# TMS320F28M35x_M3 register map
Vendor: Texas Instruments; Series: C2000 Concerto F28M35x; File version: 0.2.0-generated
CPU: CM3 r2p1, little endian, no MPU, no FPU, 3 interrupt priority bits
Registers are 32-bit, read-write, reset 0x0 unless marked. A register's access mark holds for its fields unless they carry their own. Offsets are from the block's base; [hi:lo] are bit positions; {n}, {i} and the like mark numbered series.

## DEVEMU — DEV EMU REGS Registers
Base 0x00000880
0x00 DEVICECNF — Device Configuration Register
0x02 PARTID 16-bit — Device ID Register
0x03 REVID 16-bit — Revision Register
{0x6+2i} CCNF{i} (i=0..4) — C28 Peripheral Configuration {i}
0x46 MEMCNF — M3 Memory Configuartion Register

## CSM — DCSM REGS Registers
Base 0x00000AE0
{0x0+2i} Z1_CSMKEY{i} (i=0..3) — CSMKEY{i} Register for C28X-Zone-1 security Zone
0x0F Z1_CR 16-bit — Status and Control Register for C28X-Zone-1 security Zone
0x10 Z1_ECSLKEY0 — ECSLKEY0 Register for C28X-Zone-1 security Zone
0x12 Z1_ECSLKEY1 — ECSLKEY1 Register for C28X-Zone-1 security Zone
0x15 Z1_EXEONLYR 16-bit — Execute-Only Select Register for flash sectors

## CPUTIMER — CPU Timer Registers
Base 0x00000C00
{0x0+8i} TIMER{i}TIM 16-bit (i=0..2) — CPU-Timer {i}, Counter Register
{0x1+8i} TIMER{i}TIMH 16-bit (i=0..2) — CPU-Timer {i}, Counter Register High
{0x2+8i} TIMER{i}PRD 16-bit (i=0..2) — CPU-Timer {i}, Period Register
{0x3+8i} TIMER{i}PRDH 16-bit (i=0..2) — CPU-Timer {i}, Period Register High
{0x4+8i} TIMER{i}TCR 16-bit (i=0..2) — CPU-Timer {i}, Control Register
{0x6+8i} TIMER{i}TPR 16-bit (i=0..2) — CPU-Timer {i}, Prescale Register
{0x7+8i} TIMER{i}TPRH 16-bit (i=0..2) — CPU-Timer {i}, Prescale Register High

## PIECTRL — Peripheral Interrupt Expansion Registers
Base 0x00000CE0
0x00 PIECTRL 16-bit — PIE, Control Register
0x01 PIEACK 16-bit — PIE, Acknowledge Register
{0x0+2i} PIEIER{i} 16-bit (i=1..12) — PIE, INT{i} Group Enable Register
{0x1+2i} PIEIFR{i} 16-bit (i=1..12) — PIE, INT{i} Group Flag Register

## FPU — Floating-Point Unit Single Precision Registers
Base 0x00000F00
0x00 RB — Repeat Block Register
  [31] RAS — Repeat block shadow active
  [30] RA — Repeat block active
  [31:29] RSIZE — Repeat block size
  [28:22] RE — Repeat block end
  [30:15] RC — Repeat count
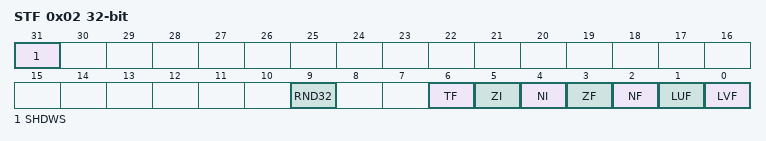
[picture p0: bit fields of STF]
0x02 STF — Floating-Point Status Register
  [31] SHDWS — Shadow mode status
  [9] RND32 — Rounding mode
  [6] TF — Test flag
  [5] ZI — Zero integer flag
  [4] NI — Negative integer flag
  [3] ZF — Zero float flag
  [2] NF — Negative flaot flag
  [1] LUF — Latched underflow
  [0] LVF — Latched overflow
{0x12+4i} R{i}H (i=0..7)

## DMA — DMA Registers
Base 0x00001000
0x00 DMACTRL 16-bit — DMA Control Register
0x01 DEBUGCTRL 16-bit — Debug Control Register
0x02 REVISION 16-bit — Peripheral Revision Register
0x04 PRIORITYCTRL1 16-bit — Priority Control Register 1
0x06 PRIORITYSTAT 16-bit — Priority Status Register
{0x0+0x20*i} DMACH{i}_MODE 16-bit (i=1..6) — DMA Channel {i} Mode Register
{0x1+0x20*i} DMACH{i}_CONTROL 16-bit (i=1..6) — DMA Channel {i} Control Register
{0x2+0x20*i} DMACH{i}_BURST_SIZE 16-bit (i=1..6) — DMA Channel {i} Burst Size Register
{0x3+0x20*i} DMACH{i}_BURST_COUNT 16-bit (i=1..6) — DMA Channel {i} Burst Count Register
{0x4+0x20*i} DMACH{i}_SRC_BURST_STEP 16-bit (i=1..6) — DMA Channel {i} Source Burst Step Size Register
{0x5+0x20*i} DMACH{i}_DST_BURST_STEP 16-bit (i=1..6) — DMA Channel {i} Destination Burst Step Size Register
{0x6+0x20*i} DMACH{i}_TRANSFER_SIZE 16-bit (i=1..6) — DMA Channel {i} Transfer Size Register
{0x7+0x20*i} DMACH{i}_TRANSFER_COUNT 16-bit (i=1..6) — DMA Channel {i} Transfer Count Register
{0x8+0x20*i} DMACH{i}_SRC_TRANSFER_STEP 16-bit (i=1..6) — DMA Channel {i} Source Transfer Step Size Register
{0x9+0x20*i} DMACH{i}_DST_TRANSFER_STEP 16-bit (i=1..6) — DMA Channel {i} Destination Transfer Step Size Register
{0xA+0x20*i} DMACH{i}_SRC_WRAP_SIZE 16-bit (i=1..6) — DMA Channel {i} Source Wrap Size Register
{0xB+0x20*i} DMACH{i}_SRC_WRAP_COUNT 16-bit (i=1..6) — DMA Channel {i} Source Wrap Count Register
{0xC+0x20*i} DMACH{i}_SRC_WRAP_STEP 16-bit (i=1..6) — DMA Channel {i} Source Wrap Step Size Register
{0xD+0x20*i} DMACH{i}_DST_WRAP_SIZE 16-bit (i=1..6) — DMA Channel {i} Destination Wrap Size Register
{0xE+0x20*i} DMACH{i}_DST_WRAP_COUNT 16-bit (i=1..6) — DMA Channel {i} Destination Wrap Count Register
{0xF+0x20*i} DMACH{i}_DST_WRAP_STEP 16-bit (i=1..6) — DMA Channel {i} Destination Wrap Step Size Register
{0x10+0x20*i} DMACH{i}_SRC_BEG_ADDR_SHADOW (i=1..6) — DMA Channel {i} Shadow Source Begin Register
{0x12+0x20*i} DMACH{i}_SRC_ADDR_SHADOW (i=1..6) — DMA Channel {i} Shadow Source Current Address Register
{0x14+0x20*i} DMACH{i}_SRC_BEG_ADDR_ACTIVE (i=1..6) — DMA Channel {i} Active Source Begin Register
{0x16+0x20*i} DMACH{i}_SRC_ADDR_ACTIVE (i=1..6) — DMA Channel {i} Active Source Current Address Register
{0x18+0x20*i} DMACH{i}_DST_BEG_ADDR_SHADOW (i=1..6) — DMA Channel {i} Shadow Destination Begin Register
{0x1A+0x20*i} DMACH{i}_DST_ADDR_SHADOW (i=1..6) — DMA Channel {i} Shadow Destination Current Address Register
{0x1C+0x20*i} DMACH{i}_DST_BEG_ADDR_ACTIVE (i=1..6) — DMA Channel {i} Active Destination Begin Register
{0x1E+0x20*i} DMACH{i}_DST_ADDR_ACTIVE (i=1..6) — DMA Channel {i} Active Destination Current Address Register
